# STM32L4x2 register map
File version: 1.6
CPU: CM4 r1p0, little endian, no MPU, no FPU, 3 interrupt priority bits
Registers are 32-bit, read-write, reset 0x0 unless marked. A register's access mark holds for its fields unless they carry their own. Offsets are from the block's base; [hi:lo] are bit positions.

## QUADSPI — QuadSPI interface
Base 0xA0001000
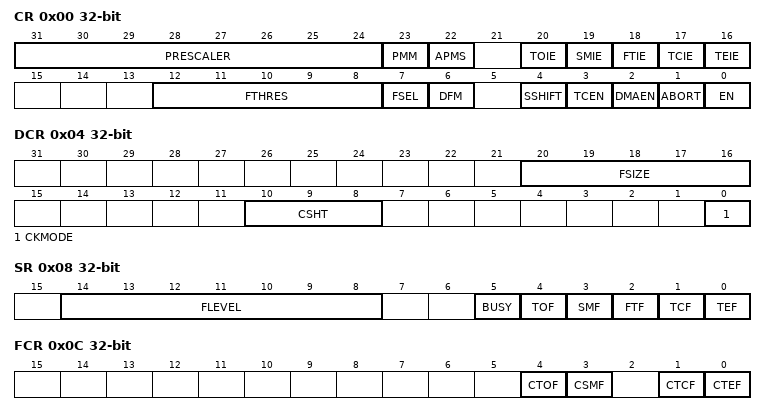
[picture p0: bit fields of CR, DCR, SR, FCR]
0x00 CR — control register
  [31:24] PRESCALER — Clock prescaler
  [23] PMM — Polling match mode
  [22] APMS — Automatic poll mode stop
  [20] TOIE — TimeOut interrupt enable
  [19] SMIE — Status match interrupt enable
  [18] FTIE — FIFO threshold interrupt enable
  [17] TCIE — Transfer complete interrupt enable
  [16] TEIE — Transfer error interrupt enable
  [12:8] FTHRES — IFO threshold level
  [7] FSEL — FLASH memory selection
  [6] DFM — Dual-flash mode
  [4] SSHIFT — Sample shift
  [3] TCEN — Timeout counter enable
  [2] DMAEN — DMA enable
  [1] ABORT — Abort request
  [0] EN — Enable
0x04 DCR — device configuration register
  [20:16] FSIZE — FLASH memory size
  [10:8] CSHT — Chip select high time
  [0] CKMODE — Mode 0 / mode 3
0x08 SR ro — status register
  [14:8] FLEVEL — FIFO level
  [5] BUSY
  [4] TOF — Timeout flag
  [3] SMF — Status match flag
  [2] FTF — FIFO threshold flag
  [1] TCF — Transfer complete flag
  [0] TEF — Transfer error flag
0x0C FCR — flag clear register
  [4] CTOF — Clear timeout flag
  [3] CSMF — Clear status match flag
  [1] CTCF — Clear transfer complete flag
  [0] CTEF — Clear transfer error flag
0x10 DLR — data length register
  [31:0] DL — Data length
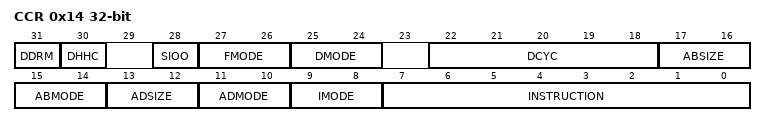
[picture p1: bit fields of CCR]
0x14 CCR — communication configuration register
  [31] DDRM — Double data rate mode
  [30] DHHC — DDR hold half cycle
  [28] SIOO — Send instruction only once mode
  [27:26] FMODE — Functional mode
  [25:24] DMODE — Data mode
  [22:18] DCYC — Number of dummy cycles
  [17:16] ABSIZE — Alternate bytes size
  [15:14] ABMODE — Alternate bytes mode
  [13:12] ADSIZE — Address size
  [11:10] ADMODE — Address mode
  [9:8] IMODE — Instruction mode
  [7:0] INSTRUCTION
0x18 AR — address register
  [31:0] ADDRESS
0x1C ABR
  [31:0] ALTERNATE
0x20 DR — data register
  [31:0] DATA
0x24 PSMKR — polling status mask register
  [31:0] MASK — Status mask
0x28 PSMAR — polling status match register
  [31:0] MATCH — Status match
0x2C PIR — polling interval register
  [15:0] INTERVAL — Polling interval
0x30 LPTR — low-power timeout register
  [15:0] TIMEOUT — Timeout period

## DBGMCU — MCU debug component
Base 0xE0042000
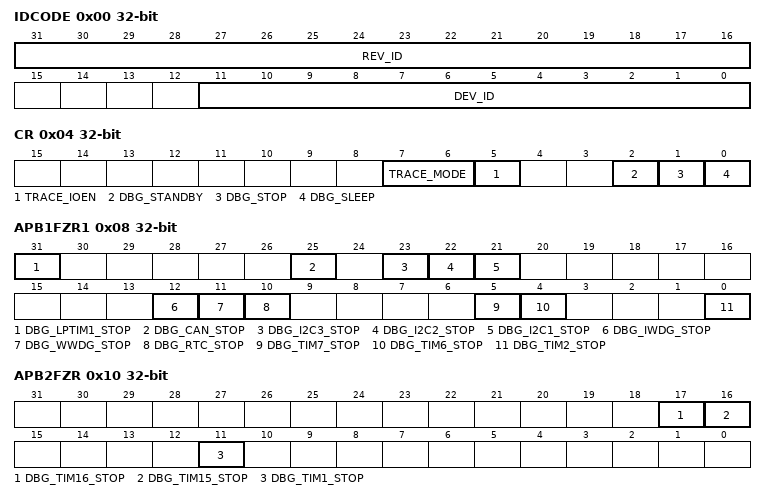
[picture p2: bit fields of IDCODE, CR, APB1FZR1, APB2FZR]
0x00 IDCODE ro — DBGMCU_IDCODE
  [31:16] REV_ID — Revision identifie
  [11:0] DEV_ID — Device identifier
0x04 CR — Debug MCU configuration register
  [7:6] TRACE_MODE — Trace pin assignment control
  [5] TRACE_IOEN — Trace pin assignment control
  [2] DBG_STANDBY — Debug Standby mode
  [1] DBG_STOP — Debug Stop mode
  [0] DBG_SLEEP — Debug Sleep mode
0x08 APB1FZR1 — Debug MCU APB1 freeze register1
  [31] DBG_LPTIM1_STOP — LPTIM1 counter stopped when core is halted
  [25] DBG_CAN_STOP — bxCAN stopped when core is halted
  [23] DBG_I2C3_STOP — I2C3 SMBUS timeout counter stopped when core is halted
  [22] DBG_I2C2_STOP — I2C2 SMBUS timeout counter stopped when core is halted
  [21] DBG_I2C1_STOP — I2C1 SMBUS timeout counter stopped when core is halted
  [12] DBG_IWDG_STOP — Independent watchdog counter stopped when core is halted
  [11] DBG_WWDG_STOP — Window watchdog counter stopped when core is halted
  [10] DBG_RTC_STOP — RTC counter stopped when core is halted
  [5] DBG_TIM7_STOP — TIM7 counter stopped when core is halted
  [4] DBG_TIM6_STOP — TIM6 counter stopped when core is halted
  [0] DBG_TIM2_STOP — TIM2 counter stopped when core is halted
0x0C APB1FZR2 — Debug MCU APB1 freeze register 2
  [5] DBG_LPTIM2_STOP — LPTIM2 counter stopped when core is halted
0x10 APB2FZR — Debug MCU APB2 freeze register
  [17] DBG_TIM16_STOP — TIM16 counter stopped when core is halted
  [16] DBG_TIM15_STOP — TIM15 counter stopped when core is halted
  [11] DBG_TIM1_STOP — TIM1 counter stopped when core is halted

## FPU — Floting point unit
Base 0xE000EF34
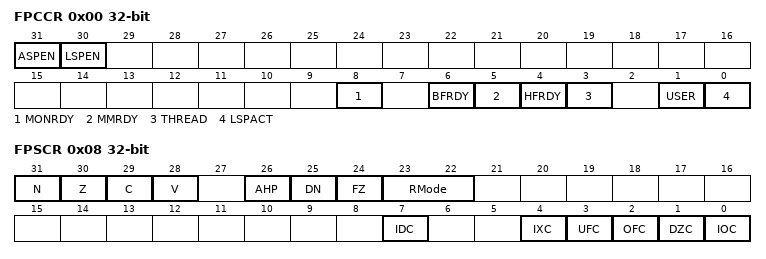
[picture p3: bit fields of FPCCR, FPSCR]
0x00 FPCCR — Floating-point context control register
  [31] ASPEN, [30] LSPEN, [8] MONRDY, [6] BFRDY, [5] MMRDY, [4] HFRDY, [3] THREAD, [1] USER, [0] LSPACT
0x04 FPCAR — Floating-point context address register
  [31:3] ADDRESS — Location of unpopulated floating-point
0x08 FPSCR — Floating-point status control register
  [31] N — Negative condition code flag
  [30] Z — Zero condition code flag
  [29] C — Carry condition code flag
  [28] V — Overflow condition code flag
  [26] AHP — Alternative half-precision control bit
  [25] DN — Default NaN mode control bit
  [24] FZ — Flush-to-zero mode control bit:
  [23:22] RMode — Rounding Mode control field
  [7] IDC — Input denormal cumulative exception bit.
  [4] IXC — Inexact cumulative exception bit
  [3] UFC — Underflow cumulative exception bit
  [2] OFC — Overflow cumulative exception bit
  [1] DZC — Division by zero cumulative exception bit.
  [0] IOC — Invalid operation cumulative exception bit

## MPU — Memory protection unit
Base 0xE000ED90
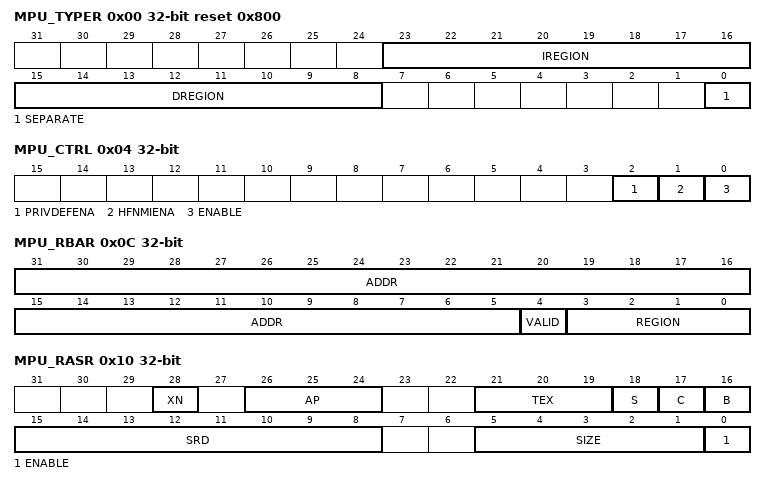
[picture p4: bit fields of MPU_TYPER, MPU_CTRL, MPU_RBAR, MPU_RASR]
0x00 MPU_TYPER ro reset 0x800 — MPU type register
  [23:16] IREGION — Number of MPU instruction regions
  [15:8] DREGION — Number of MPU data regions
  [0] SEPARATE — Separate flag
0x04 MPU_CTRL ro — MPU control register
  [2] PRIVDEFENA — Enable priviliged software access to default memory map
  [1] HFNMIENA — Enables the operation of MPU during hard fault
  [0] ENABLE — Enables the MPU
0x08 MPU_RNR — MPU region number register
  [7:0] REGION — MPU region
0x0C MPU_RBAR — MPU region base address register
  [31:5] ADDR — Region base address field
  [4] VALID — MPU region number valid
  [3:0] REGION — MPU region field
0x10 MPU_RASR — MPU region attribute and size register
  [28] XN — Instruction access disable bit
  [26:24] AP — Access permission
  [21:19] TEX — memory attribute
  [18] S — Shareable memory attribute
  [17] C — memory attribute
  [16] B — memory attribute
  [15:8] SRD — Subregion disable bits
  [5:1] SIZE — Size of the MPU protection region
  [0] ENABLE — Region enable bit.

## STK — SysTick timer
Base 0xE000E010
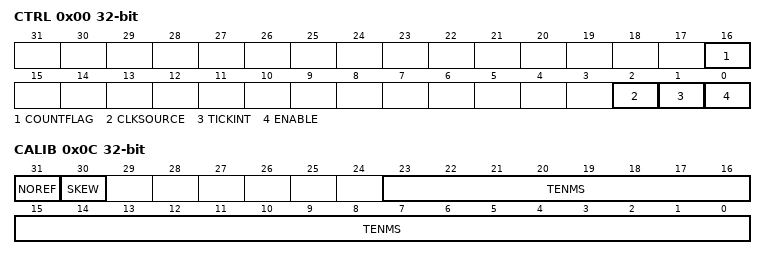
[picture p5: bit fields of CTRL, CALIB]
0x00 CTRL — SysTick control and status register
  [16] COUNTFLAG
  [2] CLKSOURCE — Clock source selection
  [1] TICKINT — SysTick exception request enable
  [0] ENABLE — Counter enable
0x04 LOAD — SysTick reload value register
  [23:0] RELOAD — RELOAD value
0x08 VAL — SysTick current value register
  [23:0] CURRENT — Current counter value
0x0C CALIB — SysTick calibration value register
  [31] NOREF — NOREF flag. Reads as zero
  [30] SKEW — SKEW flag: Indicates whether the TENMS value is exact
  [23:0] TENMS — Calibration value

## NVIC_STIR — Nested vectored interrupt controller
Base 0xE000EF00
0x00 STIR — Software trigger interrupt register
  [8:0] INTID — Software generated interrupt ID

## FPU_CPACR — Floating point unit CPACR
Base 0xE000ED88
0x00 CPACR — Coprocessor access control register
  [23:20] CP

## SCB_ACTRL — System control block ACTLR
Base 0xE000E008
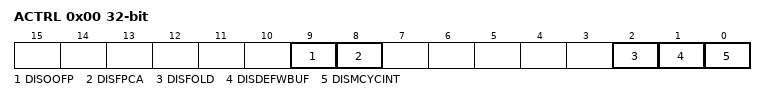
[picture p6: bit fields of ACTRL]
0x00 ACTRL — Auxiliary control register
  [9] DISOOFP, [8] DISFPCA, [2] DISFOLD, [1] DISDEFWBUF, [0] DISMCYCINT
